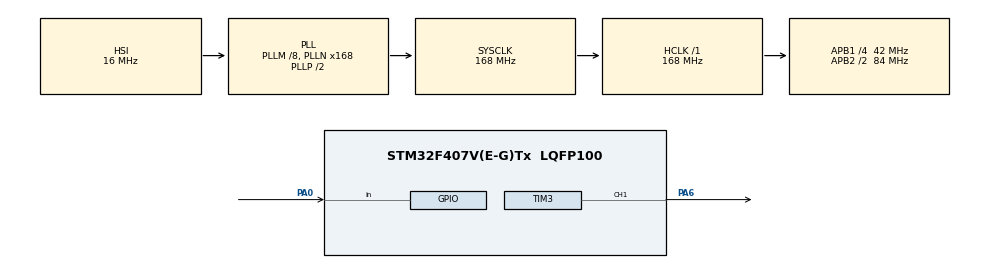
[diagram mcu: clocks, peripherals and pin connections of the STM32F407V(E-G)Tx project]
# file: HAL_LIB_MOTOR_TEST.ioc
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Mcu.Family=STM32F4
Mcu.Name=STM32F407V(E-G)Tx
Mcu.Package=LQFP100
NVIC.PriorityGroup=NVIC_PRIORITYGROUP_4
PA0-WKUP.GPIO_PuPd=GPIO_PULLDOWN
PA0-WKUP.Signal=GPIO_Input
PA6.Signal=S_TIM3_CH1
ProjectManager.HeapSize=0x200
ProjectManager.StackSize=0x400
ProjectManager.TargetToolchain=STM32CubeIDE
RCC.48MHZClocksFreq_Value=84000000
RCC.AHBFreq_Value=168000000
RCC.APB1CLKDivider=RCC_HCLK_DIV4
RCC.APB1Freq_Value=42000000
RCC.APB1TimFreq_Value=84000000
RCC.APB2CLKDivider=RCC_HCLK_DIV2
RCC.APB2Freq_Value=84000000
RCC.APB2TimFreq_Value=168000000
RCC.CortexFreq_Value=168000000
RCC.HCLKFreq_Value=168000000
RCC.HSE_VALUE=25000000
RCC.HSI_VALUE=16000000
RCC.LSE_VALUE=32768
RCC.PLLM=8
RCC.PLLN=168
RCC.SYSCLKFreq_VALUE=168000000
RCC.SYSCLKSource=RCC_SYSCLKSOURCE_PLLCLK
RCC.VCOOutputFreq_Value=336000000
SH.S_TIM3_CH1.0=TIM3_CH1,PWM Generation1 CH1
TIM3.Channel-PWM\ Generation1\ CH1=TIM_CHANNEL_1
TIM3.Period=19999
TIM3.Prescaler=83
board=custom

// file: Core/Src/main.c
/* USER CODE BEGIN Header */
/**
  ******************************************************************************
  * @file           : main.c
  * @brief          : Main program body
  ******************************************************************************
  * @attention
  *
  * Copyright (c) 2022 STMicroelectronics.
  * All rights reserved.
  *
  * This software is licensed under terms that can be found in the LICENSE file
  * in the root directory of this software component.
  * If no LICENSE file comes with this software, it is provided AS-IS.
  *
  ******************************************************************************
  */
/* USER CODE END Header */
#include "main.h"

TIM_HandleTypeDef htim3;

/* USER CODE BEGIN PV */
uint8_t count=0;
int i=1800;
int j=1200;
int k=1200;
/* USER CODE END PV */

void SystemClock_Config(void);
static void MX_GPIO_Init(void);
static void MX_TIM3_Init(void);

int main(void)
{

  /* MCU Configuration--------------------------------------------------------*/

  /* Reset of all peripherals, Initializes the Flash interface and the Systick. */
  HAL_Init();

  /* Configure the system clock */
  SystemClock_Config();

  /* Initialize all configured peripherals */
  MX_GPIO_Init();
  MX_TIM3_Init();
  /* USER CODE BEGIN 2 */
  HAL_TIM_PWM_Start(&htim3, TIM_CHANNEL_1);
  __HAL_TIM_SET_COMPARE(&htim3, TIM_CHANNEL_1, 1500);
  HAL_Delay(7000);
  //__HAL_TIM_SET_COMPARE(&htim3, TIM_CHANNEL_1, 1900);

  /* USER CODE END 2 */

  /* Infinite loop */
  while (1)
  {

    /* USER CODE BEGIN 3 */
	  //__HAL_TIM_SET_COMPARE(&htim3, TIM_CHANNEL_1, 1900);
	  if(HAL_GPIO_ReadPin(GPIOA, GPIO_PIN_0))
	  {
		  while(HAL_GPIO_ReadPin(GPIOA, GPIO_PIN_0));
		  HAL_Delay(100);

		  count++;
	  }

	  if (count % 5 == 0){
		  while(j<1500){
			  j++;
		  __HAL_TIM_SET_COMPARE(&htim3, TIM_CHANNEL_1, j);
		  HAL_Delay(10);
		  if(i==1501) break;
		  }
		  __HAL_TIM_SET_COMPARE(&htim3, TIM_CHANNEL_1, 1500);
	  }

	  else if (count % 5 == 1){
		  __HAL_TIM_SET_COMPARE(&htim3, TIM_CHANNEL_1, 1800);
	  }

	  else if (count % 5 == 2){

		  while(i>1500){
			  --i;
		  __HAL_TIM_SET_COMPARE(&htim3, TIM_CHANNEL_1, i);
		  HAL_Delay(10);
		  if(i==1501) break;
		  }
		  __HAL_TIM_SET_COMPARE(&htim3, TIM_CHANNEL_1, 1500);
	  }

	  else if (count % 5 == 3){
		  __HAL_TIM_SET_COMPARE(&htim3, TIM_CHANNEL_1, 1200);
	  }

	  else if (count % 5 == 4){
		  while(k<1500){
			  k++;
		  __HAL_TIM_SET_COMPARE(&htim3, TIM_CHANNEL_1, k);
		  HAL_Delay(10);
		  if(i==1501) break;
		  }
		  __HAL_TIM_SET_COMPARE(&htim3, TIM_CHANNEL_1, 1500);
	  }

  }
  /* USER CODE END 3 */
}

void SystemClock_Config(void)
{
  RCC_OscInitTypeDef RCC_OscInitStruct = {0};
  RCC_ClkInitTypeDef RCC_ClkInitStruct = {0};

  /** Configure the main internal regulator output voltage
  */
  __HAL_RCC_PWR_CLK_ENABLE();
  __HAL_PWR_VOLTAGESCALING_CONFIG(PWR_REGULATOR_VOLTAGE_SCALE1);
  /** Initializes the RCC Oscillators according to the specified parameters
  * in the RCC_OscInitTypeDef structure.
  */
  RCC_OscInitStruct.OscillatorType = RCC_OSCILLATORTYPE_HSI;
  RCC_OscInitStruct.HSIState = RCC_HSI_ON;
  RCC_OscInitStruct.HSICalibrationValue = RCC_HSICALIBRATION_DEFAULT;
  RCC_OscInitStruct.PLL.PLLState = RCC_PLL_ON;
  RCC_OscInitStruct.PLL.PLLSource = RCC_PLLSOURCE_HSI;
  RCC_OscInitStruct.PLL.PLLM = 8;
  RCC_OscInitStruct.PLL.PLLN = 168;
  RCC_OscInitStruct.PLL.PLLP = RCC_PLLP_DIV2;
  RCC_OscInitStruct.PLL.PLLQ = 4;
  if (HAL_RCC_OscConfig(&RCC_OscInitStruct) != HAL_OK)
  {
    Error_Handler();
  }
  /** Initializes the CPU, AHB and APB buses clocks
  */
  RCC_ClkInitStruct.ClockType = RCC_CLOCKTYPE_HCLK|RCC_CLOCKTYPE_SYSCLK
                              |RCC_CLOCKTYPE_PCLK1|RCC_CLOCKTYPE_PCLK2;
  RCC_ClkInitStruct.SYSCLKSource = RCC_SYSCLKSOURCE_PLLCLK;
  RCC_ClkInitStruct.AHBCLKDivider = RCC_SYSCLK_DIV1;
  RCC_ClkInitStruct.APB1CLKDivider = RCC_HCLK_DIV4;
  RCC_ClkInitStruct.APB2CLKDivider = RCC_HCLK_DIV2;

  if (HAL_RCC_ClockConfig(&RCC_ClkInitStruct, FLASH_LATENCY_5) != HAL_OK)
  {
    Error_Handler();
  }
}

static void MX_TIM3_Init(void)
{

  TIM_MasterConfigTypeDef sMasterConfig = {0};
  TIM_OC_InitTypeDef sConfigOC = {0};

  htim3.Instance = TIM3;
  htim3.Init.Prescaler = 83;
  htim3.Init.CounterMode = TIM_COUNTERMODE_UP;
  htim3.Init.Period = 19999;
  htim3.Init.ClockDivision = TIM_CLOCKDIVISION_DIV1;
  htim3.Init.AutoReloadPreload = TIM_AUTORELOAD_PRELOAD_DISABLE;
  if (HAL_TIM_PWM_Init(&htim3) != HAL_OK)
  {
    Error_Handler();
  }
  sMasterConfig.MasterOutputTrigger = TIM_TRGO_RESET;
  sMasterConfig.MasterSlaveMode = TIM_MASTERSLAVEMODE_DISABLE;
  if (HAL_TIMEx_MasterConfigSynchronization(&htim3, &sMasterConfig) != HAL_OK)
  {
    Error_Handler();
  }
  sConfigOC.OCMode = TIM_OCMODE_PWM1;
  sConfigOC.Pulse = 0;
  sConfigOC.OCPolarity = TIM_OCPOLARITY_HIGH;
  sConfigOC.OCFastMode = TIM_OCFAST_DISABLE;
  if (HAL_TIM_PWM_ConfigChannel(&htim3, &sConfigOC, TIM_CHANNEL_1) != HAL_OK)
  {
    Error_Handler();
  }
  HAL_TIM_MspPostInit(&htim3);

}

static void MX_GPIO_Init(void)
{
  GPIO_InitTypeDef GPIO_InitStruct = {0};

  /* GPIO Ports Clock Enable */
  __HAL_RCC_GPIOA_CLK_ENABLE();

  /*Configure GPIO pin : PA0 */
  GPIO_InitStruct.Pin = GPIO_PIN_0;
  GPIO_InitStruct.Mode = GPIO_MODE_INPUT;
  GPIO_InitStruct.Pull = GPIO_PULLDOWN;
  HAL_GPIO_Init(GPIOA, &GPIO_InitStruct);

}

void Error_Handler(void)
{
  __disable_irq();
  while (1)
  {
  }
}
